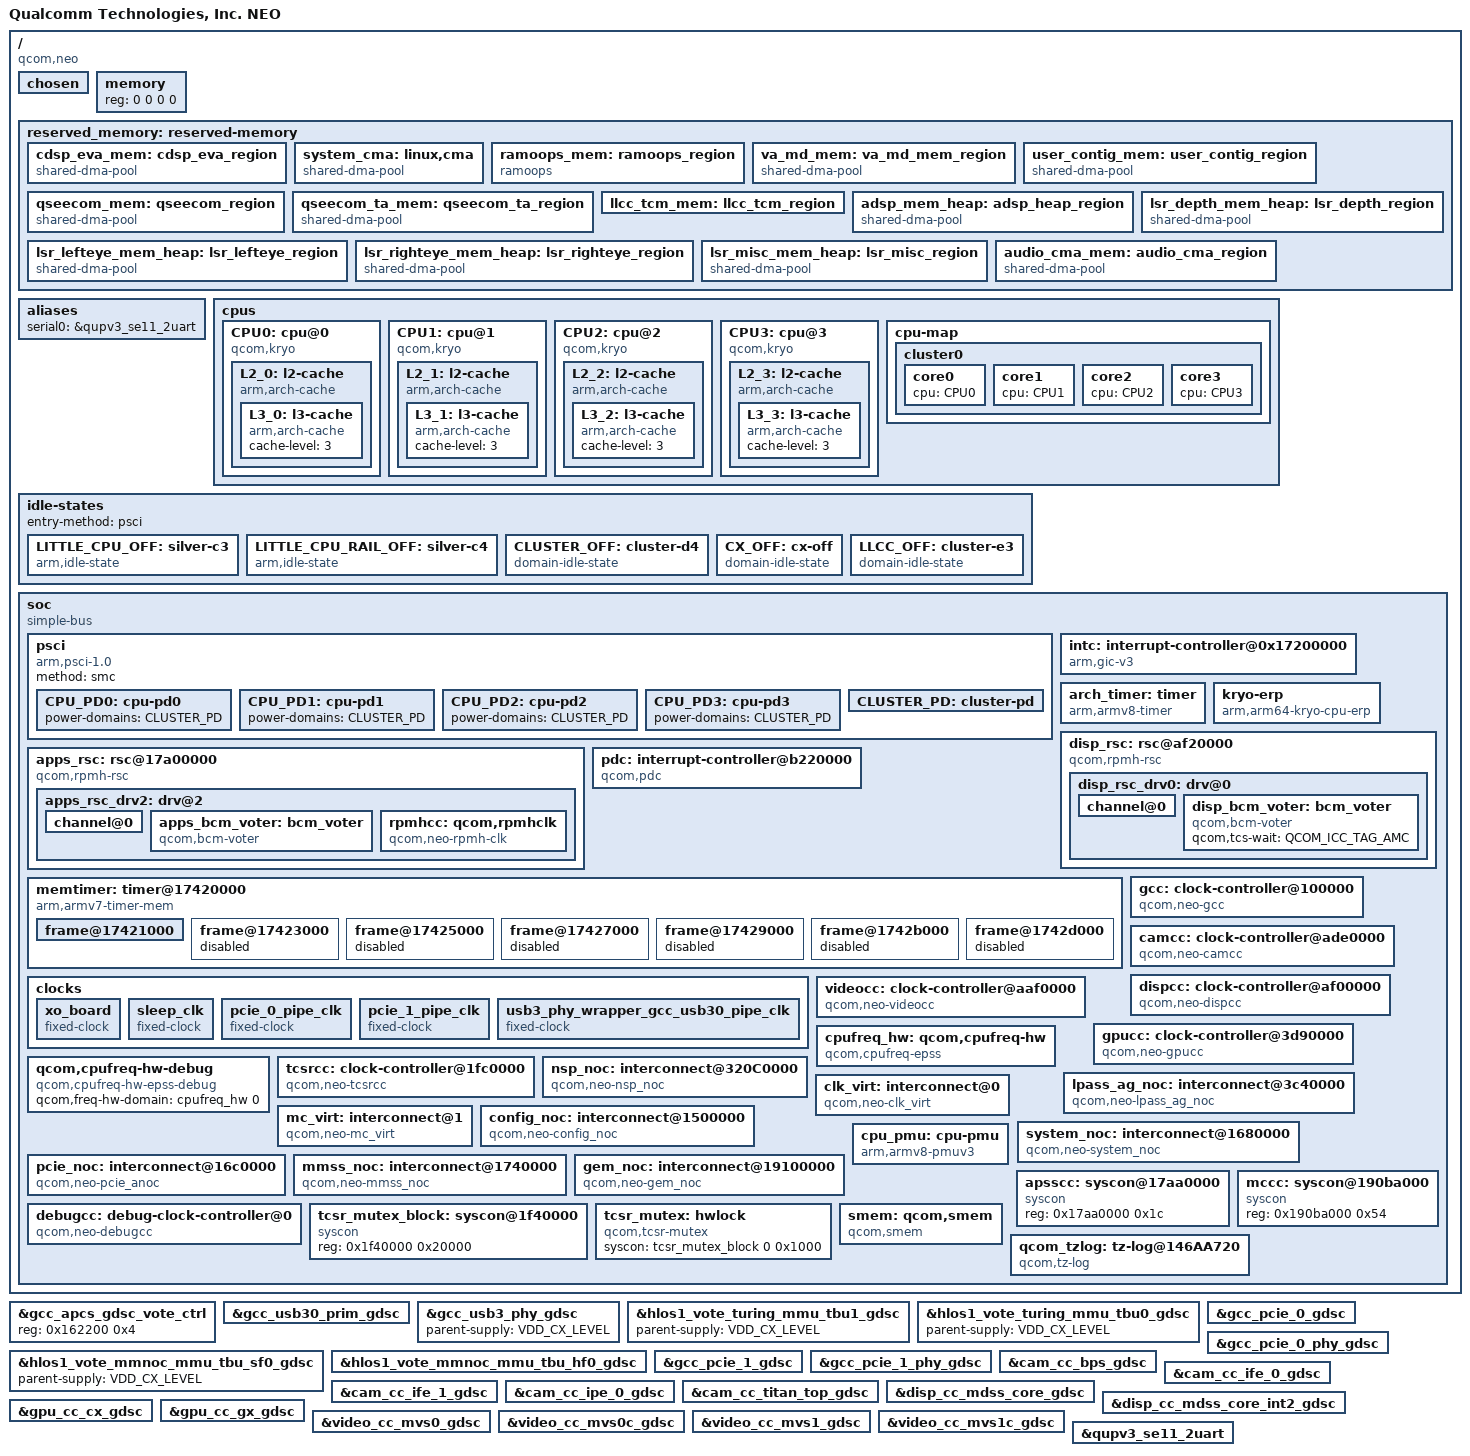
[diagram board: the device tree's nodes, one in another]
#include <dt-bindings/interrupt-controller/arm-gic.h>
#include <dt-bindings/clock/qcom,rpmh.h>
#include <dt-bindings/clock/qcom,gcc-neo.h>
#include <dt-bindings/clock/qcom,gpucc-neo.h>
#include <dt-bindings/clock/qcom,camcc-neo.h>
#include <dt-bindings/clock/qcom,dispcc-neo.h>
#include <dt-bindings/clock/qcom,tcsrcc-neo.h>
#include <dt-bindings/clock/qcom,videocc-neo.h>
#include <dt-bindings/interconnect/qcom,icc.h>
#include <dt-bindings/interconnect/qcom,neo.h>
#include <dt-bindings/soc/qcom,rpmh-rsc.h>

/ {
	model = "Qualcomm Technologies, Inc. NEO";
	compatible = "qcom,neo";
	qcom,msm-id = <525 0x10000>;
	interrupt-parent = <&intc>;

	#address-cells = <2>;
	#size-cells = <2>;

	chosen: chosen {
		bootargs = " rcupdate.rcu_expedited=1 rcu_nocbs=0-7 kpti=off log_buf_len=256K pcie_ports=compat console=ttyMSM0,115200,n8 loglevel=6 cpufreq.default_governor=performance swiotlb=noforce cgroup.memory=nokmem,nosocket allow_file_spec_access msm_rtb.filter=0x237 disable_dma32=on ftrace_dump_on_oops net.ifnames=0";
	};

	memory { device_type = "memory"; reg = <0 0 0 0>; };

	reserved_memory: reserved-memory { };

	aliases: aliases {
		serial0 = &qupv3_se11_2uart;
	};

	cpus {
		#address-cells = <2>;
		#size-cells = <0>;

		CPU0: cpu@0 {
			device_type = "cpu";
			compatible = "qcom,kryo";
			reg = <0x0 0x0>;
			enable-method = "psci";
			next-level-cache = <&L2_0>;
			cpu-idle-states = <&LITTLE_CPU_OFF &LITTLE_CPU_RAIL_OFF>;
			power-domains = <&CPU_PD0>;
			power-domain-names = "psci";
			capacity-dmips-mhz = <1024>;
			dynamic-power-coefficient = <100>;
			#cooling-cells = <2>;
			qcom,freq-domain = <&cpufreq_hw 0>;
			L2_0: l2-cache {
				compatible = "arm,arch-cache";
				cache-level = <2>;
				next-level-cache = <&L3_0>;

				L3_0: l3-cache {
					compatible = "arm,arch-cache";
					cache-level = <3>;
				};
			};
		};

		CPU1: cpu@1 {
			device_type = "cpu";
			compatible = "qcom,kryo";
			reg = <0x0 0x100>;
			enable-method = "psci";
			next-level-cache = <&L2_1>;
			cpu-idle-states = <&LITTLE_CPU_OFF &LITTLE_CPU_RAIL_OFF>;
			power-domains = <&CPU_PD1>;
			power-domain-names = "psci";
			capacity-dmips-mhz = <1024>;
			dynamic-power-coefficient = <100>;
			#cooling-cells = <2>;
			qcom,freq-domain = <&cpufreq_hw 0>;
			L2_1: l2-cache {
				compatible = "arm,arch-cache";
				cache-level = <2>;
				next-level-cache = <&L3_1>;

				L3_1: l3-cache {
					compatible = "arm,arch-cache";
					cache-level = <3>;
				};
			};
		};

		CPU2: cpu@2 {
			device_type = "cpu";
			compatible = "qcom,kryo";
			reg = <0x0 0x200>;
			enable-method = "psci";
			next-level-cache = <&L2_2>;
			cpu-idle-states = <&LITTLE_CPU_OFF &LITTLE_CPU_RAIL_OFF>;
			power-domains = <&CPU_PD2>;
			power-domain-names = "psci";
			capacity-dmips-mhz = <1024>;
			dynamic-power-coefficient = <100>;
			#cooling-cells = <2>;
			qcom,freq-domain = <&cpufreq_hw 0>;
			L2_2: l2-cache {
				compatible = "arm,arch-cache";
				cache-level = <2>;
				next-level-cache = <&L3_2>;

				L3_2: l3-cache {
					compatible = "arm,arch-cache";
					cache-level = <3>;
				};
			};
		};

		CPU3: cpu@3 {
			device_type = "cpu";
			compatible = "qcom,kryo";
			reg = <0x0 0x300>;
			enable-method = "psci";
			next-level-cache = <&L2_3>;
			cpu-idle-states = <&LITTLE_CPU_OFF &LITTLE_CPU_RAIL_OFF>;
			power-domains = <&CPU_PD3>;
			power-domain-names = "psci";
			capacity-dmips-mhz = <1024>;
			dynamic-power-coefficient = <100>;
			#cooling-cells = <2>;
			qcom,freq-domain = <&cpufreq_hw 0>;
			L2_3: l2-cache {
				compatible = "arm,arch-cache";
				cache-level = <2>;
				next-level-cache = <&L3_3>;

				L3_3: l3-cache {
					compatible = "arm,arch-cache";
					cache-level = <3>;
				};
			};
		};

		cpu-map {
			cluster0 {
				core0 {
					cpu = <&CPU0>;
				};

				core1 {
					cpu = <&CPU1>;
				};

				core2 {
					cpu = <&CPU2>;
				};

				core3 {
					cpu = <&CPU3>;
				};
			};
		};
	};

	idle-states {
		entry-method = "psci";

		LITTLE_CPU_OFF: silver-c3 {  /* C3 */
			compatible = "arm,idle-state";
			idle-state-name = "pc";
			entry-latency-us = <549>;
			exit-latency-us = <901>;
			min-residency-us = <1774>;
			arm,psci-suspend-param = <0x40000003>;
			local-timer-stop;
		};

		LITTLE_CPU_RAIL_OFF: silver-c4 {  /* C4 */
			compatible = "arm,idle-state";
			idle-state-name = "rail-pc";
			entry-latency-us = <702>;
			exit-latency-us = <915>;
			min-residency-us = <4001>;
			arm,psci-suspend-param = <0x40000004>;
			local-timer-stop;
		};

		CLUSTER_OFF: cluster-d4 { /* D4 */
			compatible = "domain-idle-state";
			idle-state-name = "l3-off";
			entry-latency-us = <2752>;
			exit-latency-us = <3048>;
			min-residency-us = <6118>;
			arm,psci-suspend-param = <0x41000044>;
		};

		CX_OFF: cx-off { /* Cx Off */
			compatible = "domain-idle-state";
			idle-state-name = "cx-off";
			entry-latency-us = <3263>;
			exit-latency-us = <4562>;
			min-residency-us = <8467>;
			arm,psci-suspend-param = <0x41002344>;
		};

		LLCC_OFF: cluster-e3 { /* E3 */
			compatible = "domain-idle-state";
			idle-state-name = "llcc-off";
			entry-latency-us = <3638>;
			exit-latency-us = <6562>;
			min-residency-us = <9826>;
			arm,psci-suspend-param = <0x4100C344>;
		};
	};

	soc: soc { };

};

#include "neo-reserved-memory.dtsi"

&reserved_memory {
	#address-cells = <2>;
	#size-cells = <2>;
	ranges;

	cdsp_eva_mem: cdsp_eva_region {
			compatible = "shared-dma-pool";
			alloc-ranges = <0x0 0x00000000 0x0 0xffffffff>;
			reusable;
			alignment = <0x0 0x400000>;
			size = <0x0 0x400000>;
	};

	/* global autoconfigured region for contiguous allocations */
	system_cma: linux,cma {
		compatible = "shared-dma-pool";
		alloc-ranges = <0x0 0x00000000 0x0 0xffffffff>;
		reusable;
		alignment = <0x0 0x400000>;
		size = <0x0 0x1000000>;
		linux,cma-default;
	};

	ramoops_mem: ramoops_region {
		compatible = "ramoops";
		alloc-ranges = <0x0 0x00000000 0xffffffff 0xffffffff>;
		size = <0x0 0x200000>;
		pmsg-size = <0x200000>;
		mem-type = <2>;
	};

	va_md_mem: va_md_mem_region {
		compatible = "shared-dma-pool";
		alloc-ranges = <0x0 0x00000000 0x0 0xffffffff>;
		reusable;
		size = <0 0x1000000>;
	};

	user_contig_mem: user_contig_region {
		compatible = "shared-dma-pool";
		alloc-ranges = <0x0 0x00000000 0x0 0xffffffff>;
		reusable;
		alignment = <0x0 0x400000>;
		size = <0x0 0x400000>;
	};

	qseecom_mem: qseecom_region {
		compatible = "shared-dma-pool";
		alloc-ranges = <0x0 0x00000000 0x0 0xffffffff>;
		reusable;
		alignment = <0x0 0x400000>;
		size = <0x0 0x400000>;
	};

	qseecom_ta_mem: qseecom_ta_region {
		compatible = "shared-dma-pool";
		alloc-ranges = <0x0 0x00000000 0x0 0xffffffff>;
		reusable;
		alignment = <0x0 0x400000>;
		size = <0x0 0x400000>;
	};

	llcc_tcm_mem: llcc_tcm_region {
		no-map;
		reg = <0x0 0x15800000 0x0 0x800000>;
	};

	adsp_mem_heap: adsp_heap_region {
		compatible = "shared-dma-pool";
		alloc-ranges = <0x0 0x00000000 0x0 0xffffffff>;
		reusable;
		alignment = <0x0 0x400000>;
		size = <0x0 0x800000>;
	};

	lsr_lefteye_mem_heap: lsr_lefteye_region {
		compatible = "shared-dma-pool";
		alloc-ranges = <0x0 0x00000000 0x0 0xffffffff>;
		no-map;
		alignment = <0x0 0x400000>;
		size = <0x0 0x1000000>;
	};

	lsr_righteye_mem_heap: lsr_righteye_region {
		compatible = "shared-dma-pool";
		alloc-ranges = <0x0 0x00000000 0x0 0xffffffff>;
		no-map;
		alignment = <0x0 0x400000>;
		size = <0x0 0x1000000>;
	};

	lsr_depth_mem_heap: lsr_depth_region {
		compatible = "shared-dma-pool";
		alloc-ranges = <0x0 0x00000000 0x0 0xffffffff>;
		no-map;
		alignment = <0x0 0x400000>;
		size = <0x0 0x100000>;
	};

	lsr_misc_mem_heap: lsr_misc_region {
		compatible = "shared-dma-pool";
		alloc-ranges = <0x0 0x00000000 0x0 0xffffffff>;
		no-map;
		alignment = <0x0 0x400000>;
		size = <0x0 0x2800000>;
	};

	audio_cma_mem: audio_cma_region {
		compatible = "shared-dma-pool";
		alloc-ranges = <0x0 0x00000000 0x0 0xffffffff>;
		reusable;
		alignment = <0x0 0x400000>;
		size = <0x0 0x1000000>;
	};
};

&soc {
	#address-cells = <1>;
	#size-cells = <1>;
	ranges = <0 0 0 0xffffffff>;
	compatible = "simple-bus";

	psci {
		compatible = "arm,psci-1.0";
		method = "smc";

		CPU_PD0: cpu-pd0 {
			#power-domain-cells = <0>;
			power-domains = <&CLUSTER_PD>;
		};

		CPU_PD1: cpu-pd1 {
			#power-domain-cells = <0>;
			power-domains = <&CLUSTER_PD>;
		};

		CPU_PD2: cpu-pd2 {
			#power-domain-cells = <0>;
			power-domains = <&CLUSTER_PD>;
		};

		CPU_PD3: cpu-pd3 {
			#power-domain-cells = <0>;
			power-domains = <&CLUSTER_PD>;
		};

		CLUSTER_PD: cluster-pd {
			#power-domain-cells = <0>;
			domain-idle-states = <&CLUSTER_OFF &CX_OFF &LLCC_OFF>;
		};
	};

	intc: interrupt-controller@0x17200000 {
		compatible = "arm,gic-v3";
		#interrupt-cells = <3>;
		interrupt-controller;
		#redistributor-regions = <1>;
		redistributor-stride = <0x0 0x20000>;
		reg = <0x17200000 0x10000>,     /* GICD */
		      <0x17260000 0x100000>;    /* GICR * 8 */
		interrupts = <GIC_PPI 9 IRQ_TYPE_LEVEL_LOW>;
	};

	arch_timer: timer {
		compatible = "arm,armv8-timer";
		interrupts = <GIC_PPI 13 (GIC_CPU_MASK_SIMPLE(8) | IRQ_TYPE_LEVEL_LOW)>,
			     <GIC_PPI 14 (GIC_CPU_MASK_SIMPLE(8) | IRQ_TYPE_LEVEL_LOW)>,
			     <GIC_PPI 11 (GIC_CPU_MASK_SIMPLE(8) | IRQ_TYPE_LEVEL_LOW)>,
			     <GIC_PPI 12 (GIC_CPU_MASK_SIMPLE(8) | IRQ_TYPE_LEVEL_LOW)>;
		clock-frequency = <19200000>;
	};

	kryo-erp {
		compatible = "arm,arm64-kryo-cpu-erp";
		interrupts = <GIC_PPI 0 IRQ_TYPE_LEVEL_HIGH>,
			     <GIC_SPI 35 IRQ_TYPE_LEVEL_HIGH>;
		interrupt-names = "l1-l2-faultirq","l3-scu-faultirq";
	};

	apps_rsc: rsc@17a00000 {
		label = "apps_rsc";
		compatible = "qcom,rpmh-rsc";
		reg = <0x17a00000 0x10000>,
		      <0x17a10000 0x10000>,
		      <0x17a20000 0x10000>;
		reg-names = "drv-0", "drv-1", "drv-2";
		qcom,drv-count = <3>;
		interrupts = <GIC_SPI 3 IRQ_TYPE_LEVEL_HIGH>,
			     <GIC_SPI 4 IRQ_TYPE_LEVEL_HIGH>,
			     <GIC_SPI 5 IRQ_TYPE_LEVEL_HIGH>;
		power-domains = <&CLUSTER_PD>;

		apps_rsc_drv2: drv@2 {
			qcom,drv-id = <2>;
			qcom,tcs-offset = <0xd00>;
			channel@0 {
				qcom,tcs-config = <ACTIVE_TCS    3>,
						  <SLEEP_TCS     2>,
						  <WAKE_TCS      2>,
						  <FAST_PATH_TCS 1>,
						  <CONTROL_TCS   0>;
			};

			apps_bcm_voter: bcm_voter {
				compatible = "qcom,bcm-voter";
			};

			rpmhcc: qcom,rpmhclk {
				compatible = "qcom,neo-rpmh-clk";
				#clock-cells = <1>;
			};
		};
	};

	disp_rsc: rsc@af20000 {
		label = "disp_rsc";
		compatible = "qcom,rpmh-rsc";
		reg = <0xaf20000 0x10000>;
		reg-names = "drv-0";
		qcom,drv-count = <1>;
		interrupts = <GIC_SPI 129 IRQ_TYPE_LEVEL_HIGH>;

		disp_rsc_drv0: drv@0 {
			qcom,drv-id = <0>;
			qcom,tcs-offset = <0x1c00>;
			channel@0 {
				qcom,tcs-config = <ACTIVE_TCS    0>,
						  <SLEEP_TCS     1>,
						  <WAKE_TCS      1>,
						  <CONTROL_TCS   0>,
						  <FAST_PATH_TCS 0>;
			};

			disp_bcm_voter: bcm_voter {
				compatible = "qcom,bcm-voter";
				qcom,tcs-wait = <QCOM_ICC_TAG_AMC>;
			};
		};
	};

	pdc: interrupt-controller@b220000 {
		compatible = "qcom,pdc", "qcom,neo-pdc";
		reg = <0xb220000 0x30000>, <0x174000f0 0x64>;
		reg-names = "pdc-interrupt-base", "apss-shared-spi-cfg";
		qcom,pdc-ranges = <0 480 94>, <94 609 31>, <125 63 1>, <126 716 12>;
		#interrupt-cells = <2>;
		interrupt-parent = <&intc>;
		interrupt-controller;
	};

	memtimer: timer@17420000 {
		#address-cells = <1>;
		#size-cells = <1>;
		ranges;
		compatible = "arm,armv7-timer-mem";
		reg = <0x17420000 0x1000>;
		clock-frequency = <19200000>;

		frame@17421000 {
			frame-number = <0>;
			interrupts = <GIC_SPI 8 IRQ_TYPE_LEVEL_HIGH>,
				     <GIC_SPI 6 IRQ_TYPE_LEVEL_HIGH>;
			reg = <0x17421000 0x1000>,
			      <0x17422000 0x1000>;
		};

		frame@17423000 {
			frame-number = <1>;
			interrupts = <GIC_SPI 9 IRQ_TYPE_LEVEL_HIGH>;
			reg = <0x17423000 0x1000>;
			status = "disabled";
		};

		frame@17425000 {
			frame-number = <2>;
			interrupts = <GIC_SPI 10 IRQ_TYPE_LEVEL_HIGH>;
			reg = <0x17425000 0x1000>;
			status = "disabled";
		};

		frame@17427000 {
			frame-number = <3>;
			interrupts = <GIC_SPI 11 IRQ_TYPE_LEVEL_HIGH>;
			reg = <0x17427000 0x1000>;
			status = "disabled";
		};

		frame@17429000 {
			frame-number = <4>;
			interrupts = <GIC_SPI 12 IRQ_TYPE_LEVEL_HIGH>;
			reg = <0x17429000 0x1000>;
			status = "disabled";
		};

		frame@1742b000 {
			frame-number = <5>;
			interrupts = <GIC_SPI 13 IRQ_TYPE_LEVEL_HIGH>;
			reg = <0x1742b000 0x1000>;
			status = "disabled";
		};

		frame@1742d000 {
			frame-number = <6>;
			interrupts = <GIC_SPI 14 IRQ_TYPE_LEVEL_HIGH>;
			reg = <0x1742d000 0x1000>;
			status = "disabled";
		};
	};

	clocks {
		xo_board: xo_board {
			compatible = "fixed-clock";
			clock-frequency = <19200000>;
			clock-output-names = "xo_board";
			#clock-cells = <0>;
		};

		sleep_clk: sleep_clk {
			compatible = "fixed-clock";
			clock-frequency = <32000>;
			clock-output-names = "sleep_clk";
			#clock-cells = <0>;
		};

		pcie_0_pipe_clk: pcie_0_pipe_clk {
			compatible = "fixed-clock";
			clock-frequency = <1000>;
			clock-output-names = "pcie_0_pipe_clk";
			#clock-cells = <0>;
		};

		pcie_1_pipe_clk: pcie_1_pipe_clk {
			compatible = "fixed-clock";
			clock-frequency = <1000>;
			clock-output-names = "pcie_1_pipe_clk";
			#clock-cells = <0>;
		};

		usb3_phy_wrapper_gcc_usb30_pipe_clk: usb3_phy_wrapper_gcc_usb30_pipe_clk {
			compatible = "fixed-clock";
			clock-frequency = <1000>;
			clock-output-names = "usb3_phy_wrapper_gcc_usb30_pipe_clk";
			#clock-cells = <0>;
		};
	};

	gcc: clock-controller@100000 {
		compatible = "qcom,neo-gcc", "syscon";
		reg = <0x100000 0x1f4200>;
		reg-name = "cc_base";
		vdd_cx-supply = <&VDD_CX_LEVEL>;
		vdd_mxa-supply = <&VDD_MXA_LEVEL>;
		clocks = <&rpmhcc RPMH_CXO_CLK>, <&sleep_clk>,
			<&pcie_0_pipe_clk>, <&pcie_1_pipe_clk>,
			<&usb3_phy_wrapper_gcc_usb30_pipe_clk>;
		clock-names = "bi_tcxo", "sleep_clk",
			"pcie_0_pipe_clk", "pcie_1_pipe_clk",
			"usb3_phy_wrapper_gcc_usb30_pipe_clk";
		#clock-cells = <1>;
		#reset-cells = <1>;
	};

	camcc: clock-controller@ade0000 {
		compatible = "qcom,neo-camcc", "syscon";
		reg = <0xade0000 0x20000>;
		reg-name = "cc_base";
		vdd_mm-supply = <&VDD_MM_LEVEL>;
		vdd_mxa-supply = <&VDD_MXA_LEVEL>;
		vdd_mxc-supply = <&VDD_MXC_LEVEL>;
		clocks = <&rpmhcc RPMH_CXO_CLK>,
			<&sleep_clk>,
			<&gcc GCC_CAMERA_AHB_CLK>;
		clock-names = "bi_tcxo",
			"sleep_clk", "iface";
		#clock-cells = <1>;
		#reset-cells = <1>;
	};

	dispcc: clock-controller@af00000 {
		compatible = "qcom,neo-dispcc", "syscon";
		reg = <0xaf00000 0x20000>;
		reg-name = "cc_base";
		vdd_mm-supply = <&VDD_MM_LEVEL>;
		vdd_mxa-supply = <&VDD_MXA_LEVEL>;
		clocks = <&rpmhcc RPMH_CXO_CLK>,
			<&rpmhcc RPMH_CXO_CLK_A>,
			<&sleep_clk>,
			<&gcc GCC_DISP_AHB_CLK>;
		clock-names = "bi_tcxo", "bi_tcxo_ao", "sleep_clk", "iface";
		#clock-cells = <1>;
		#reset-cells = <1>;
	};

	videocc: clock-controller@aaf0000 {
		compatible = "qcom,neo-videocc", "syscon";
		reg = <0xaaf0000 0x10000>;
		reg-name = "cc_base";
		vdd_mm-supply = <&VDD_MM_LEVEL>;
		vdd_mxc-supply = <&VDD_MXC_LEVEL>;
		clocks = <&rpmhcc RPMH_CXO_CLK>,
			<&sleep_clk>,
			<&gcc GCC_VIDEO_AHB_CLK>;
		clock-names = "bi_tcxo", "sleep_clk",
			"iface";
		#clock-cells = <1>;
		#reset-cells = <1>;
	};

	gpucc: clock-controller@3d90000 {
		compatible = "qcom,neo-gpucc", "syscon";
		reg = <0x3d90000 0xa000>;
		reg-name = "cc_base";
		vdd_cx-supply = <&VDD_CX_LEVEL>;
		vdd_mxa-supply = <&VDD_MXA_LEVEL>;
		clocks = <&rpmhcc RPMH_CXO_CLK>,
			<&gcc GCC_GPU_GPLL0_CLK_SRC>,
			<&gcc GCC_GPU_GPLL0_DIV_CLK_SRC>;
		clock-names = "bi_tcxo",
			"gpll0_out_main",
			"gpll0_out_main_div";
		#clock-cells = <1>;
		#reset-cells = <1>;
	};

	cpufreq_hw: qcom,cpufreq-hw {
		compatible = "qcom,cpufreq-epss";
		reg = <0x17d91000 0x1000>;
		reg-names = "freq-domain0";
		clocks = <&rpmhcc RPMH_CXO_CLK>, <&gcc GCC_GPLL0>;
		clock-names = "xo", "alternate";
		interrupts = <GIC_SPI 30 IRQ_TYPE_LEVEL_HIGH>;
		interrupt-names = "dcvsh0_int";
		#freq-domain-cells = <1>;
	};

	qcom,cpufreq-hw-debug {
		compatible = "qcom,cpufreq-hw-epss-debug";
		qcom,freq-hw-domain = <&cpufreq_hw 0>;
	};

	tcsrcc: clock-controller@1fc0000 {
		compatible = "qcom,neo-tcsrcc", "syscon";
		reg = <0x1fc0000 0x30000>;
		reg-name = "cc_base";
		#clock-cells = <1>;
		#reset-cells = <1>;
	};

	nsp_noc: interconnect@320C0000 {
		reg = <0x320C0000 0x10>;
		compatible = "qcom,neo-nsp_noc";
		qcom,bcm-voter-names = "hlos";
		qcom,bcm-voters = <&apps_bcm_voter>;
		#interconnect-cells = <1>;
	};

	lpass_ag_noc: interconnect@3c40000 {
		reg = <0x3c40000 0x10>;
		compatible = "qcom,neo-lpass_ag_noc";
		qcom,bcm-voter-names = "hlos";
		qcom,bcm-voters = <&apps_bcm_voter>;
		#interconnect-cells = <1>;
	};

	clk_virt: interconnect@0 {
		compatible = "qcom,neo-clk_virt";
		qcom,bcm-voter-names = "hlos";
		qcom,bcm-voters = <&apps_bcm_voter>;
		#interconnect-cells = <1>;
	};

	mc_virt: interconnect@1 {
		compatible = "qcom,neo-mc_virt";
		qcom,bcm-voter-names = "hlos", "disp";
		qcom,bcm-voters = <&apps_bcm_voter>, <&disp_bcm_voter>;
		#interconnect-cells = <1>;
	};

	config_noc: interconnect@1500000 {
		reg = <0x1500000 0x10>;
		compatible = "qcom,neo-config_noc";
		qcom,bcm-voter-names = "hlos";
		qcom,bcm-voters = <&apps_bcm_voter>;
		#interconnect-cells = <1>;
	};

	system_noc: interconnect@1680000 {
		reg = <0x1680000 0x29080>;
		compatible = "qcom,neo-system_noc";
		qcom,bcm-voter-names = "hlos";
		qcom,bcm-voters = <&apps_bcm_voter>;
		#interconnect-cells = <1>;
		clocks = <&gcc GCC_AGGRE_USB3_PRIM_AXI_CLK>;
	};

	pcie_noc: interconnect@16c0000 {
		reg = <0x16c0000 0xA080>;
		compatible = "qcom,neo-pcie_anoc";
		qcom,bcm-voter-names = "hlos";
		qcom,bcm-voters = <&apps_bcm_voter>;
		#interconnect-cells = <1>;
		clocks =  <&gcc GCC_AGGRE_NOC_PCIE_1_AXI_CLK>,
			<&gcc GCC_CFG_NOC_PCIE_ANOC_AHB_CLK>;
	};

	mmss_noc: interconnect@1740000 {
		reg = <0x1740000 0x1F100>;
		compatible = "qcom,neo-mmss_noc";
		qcom,bcm-voter-names = "hlos", "disp";
		qcom,bcm-voters = <&apps_bcm_voter>, <&disp_bcm_voter>;
		#interconnect-cells = <1>;
	};

	gem_noc: interconnect@19100000 {
		reg = <0x19100000 0xA2080>;
		compatible = "qcom,neo-gem_noc";
		qcom,bcm-voter-names = "hlos", "disp";
		qcom,bcm-voters = <&apps_bcm_voter>, <&disp_bcm_voter>;
		#interconnect-cells = <1>;
	};

	cpu_pmu: cpu-pmu {
		compatible = "arm,armv8-pmuv3";
		qcom,irq-is-percpu;
		interrupts = <GIC_PPI 7 IRQ_TYPE_LEVEL_LOW>;
	};

	apsscc: syscon@17aa0000 {
		compatible = "syscon";
		reg = <0x17aa0000 0x1c>;
	};

	mccc: syscon@190ba000 {
		compatible = "syscon";
		reg = <0x190ba000 0x54>;
	};

	debugcc: debug-clock-controller@0 {
		compatible = "qcom,neo-debugcc";
		qcom,gcc = <&gcc>;
		qcom,videocc = <&videocc>;
		qcom,camcc = <&camcc>;
		qcom,gpucc = <&gpucc>;
		qcom,dispcc = <&dispcc>;
		qcom,apsscc = <&apsscc>;
		qcom,mccc = <&mccc>;
		clock-names = "xo_clk_src",
				"gcc",
				"videocc",
				"dispcc",
				"camcc",
				"gpucc";
		clocks = <&rpmhcc RPMH_CXO_CLK>,
			<&gcc 0>,
			<&videocc 0>,
			<&dispcc 0>,
			<&camcc 0>,
			<&gpucc 0>;
		#clock-cells = <1>;
	};

	tcsr_mutex_block: syscon@1f40000 {
		compatible = "syscon";
		reg = <0x1f40000 0x20000>;
	};

	tcsr_mutex: hwlock {
		compatible = "qcom,tcsr-mutex";
		syscon = <&tcsr_mutex_block 0 0x1000>;
		#hwlock-cells = <1>;
	};

	smem: qcom,smem {
		compatible = "qcom,smem";
		memory-region = <&smem_mem>;
		hwlocks = <&tcsr_mutex 3>;
	};

	qcom_tzlog: tz-log@146AA720 {
		compatible = "qcom,tz-log";
		reg = <0x146AA720 0x3000>;
		qcom,hyplog-enabled;
		hyplog-address-offset = <0x410>;
		hyplog-size-offset = <0x414>;
		tmecrashdump-address-offset = <0x808a0000>;
	};

};

#include "neo-dma-heaps.dtsi"
#include "neo-pinctrl.dtsi"
#include "anorak-gdsc.dtsi"
#include "neo-qupv3.dtsi"

&gcc_apcs_gdsc_vote_ctrl {
	reg = <0x162200 0x4>;
};

&gcc_usb30_prim_gdsc {
	parent-supply = <&VDD_CX_LEVEL>;
	qcom,support-hw-trigger;
	status = "ok";
};

&gcc_usb3_phy_gdsc {
	parent-supply = <&VDD_CX_LEVEL>;
	status = "ok";
};

&hlos1_vote_turing_mmu_tbu1_gdsc {
	parent-supply = <&VDD_CX_LEVEL>;
	status = "ok";
};

&hlos1_vote_turing_mmu_tbu0_gdsc {
	parent-supply = <&VDD_CX_LEVEL>;
	status = "ok";
};

&hlos1_vote_mmnoc_mmu_tbu_sf0_gdsc {
	parent-supply = <&VDD_CX_LEVEL>;
	status = "ok";
};

&hlos1_vote_mmnoc_mmu_tbu_hf0_gdsc {
	parent-supply = <&VDD_CX_LEVEL>;
	reg = <0x18d204 0x4>;
	status = "ok";
};

&gcc_pcie_0_gdsc {
	parent-supply = <&VDD_CX_LEVEL>;
	status = "ok";
	/delete-property/ qcom,support-hw-trigger;
	qcom,collapse-vote = <&gcc_apcs_gdsc_vote_ctrl &gcc_apcs_gdsc_sleep_ctrl 0>;
};

&gcc_pcie_0_phy_gdsc {
	parent-supply = <&VDD_MXA_LEVEL>;
	status = "ok";
	qcom,collapse-vote = <&gcc_apcs_gdsc_vote_ctrl &gcc_apcs_gdsc_sleep_ctrl 3>;
};

&gcc_pcie_1_gdsc {
	parent-supply = <&VDD_CX_LEVEL>;
	status = "ok";
	qcom,collapse-vote = <&gcc_apcs_gdsc_vote_ctrl &gcc_apcs_gdsc_sleep_ctrl 1>;
};

&gcc_pcie_1_phy_gdsc {
	parent-supply = <&VDD_MXA_LEVEL>;
	status = "ok";
	qcom,collapse-vote = <&gcc_apcs_gdsc_vote_ctrl &gcc_apcs_gdsc_sleep_ctrl 4>;
};

&cam_cc_bps_gdsc {
	clocks = <&gcc GCC_CAMERA_AHB_CLK>;
	clock-names = "ahb_clk";
	parent-supply = <&VDD_MM_MXC_VOTER_LEVEL>;
	reg = <0xadf0004 0x4>;
	status = "ok";
};

&cam_cc_ife_0_gdsc {
	clocks = <&gcc GCC_CAMERA_AHB_CLK>;
	clock-names = "ahb_clk";
	parent-supply = <&VDD_MM_MXC_VOTER_LEVEL>;
	reg = <0xadf1004 0x4>;
	status = "ok";
};

&cam_cc_ife_1_gdsc {
	clocks = <&gcc GCC_CAMERA_AHB_CLK>;
	clock-names = "ahb_clk";
	parent-supply = <&VDD_MM_MXC_VOTER_LEVEL>;
	reg = <0xadf2004 0x4>;
	status = "ok";
};

&cam_cc_ipe_0_gdsc {
	clocks = <&gcc GCC_CAMERA_AHB_CLK>;
	clock-names = "ahb_clk";
	parent-supply = <&VDD_MM_MXC_VOTER_LEVEL>;
	reg = <0xadf03b8 0x4>;
	status = "ok";
};

&cam_cc_titan_top_gdsc {
	clocks = <&gcc GCC_CAMERA_AHB_CLK>;
	clock-names = "ahb_clk";
	parent-supply = <&VDD_MM_MXC_VOTER_LEVEL>;
	reg = <0xadf4000 0x4>;
	status = "ok";
};

&disp_cc_mdss_core_gdsc {
	clocks = <&gcc GCC_DISP_AHB_CLK>;
	clock-names = "ahb_clk";
	parent-supply = <&VDD_MM_LEVEL>;
	status = "ok";
};

&disp_cc_mdss_core_int2_gdsc {
	clocks = <&gcc GCC_DISP_AHB_CLK>;
	clock-names = "ahb_clk";
	parent-supply = <&VDD_MM_LEVEL>;
	status = "ok";
};

&gpu_cc_cx_gdsc {
	clocks = <&gcc GCC_GPU_CFG_AHB_CLK>;
	clock-names = "ahb_clk";
	parent-supply = <&VDD_CX_LEVEL>;
	status = "ok";
};

&gpu_cc_gx_gdsc {
	clocks = <&gcc GCC_GPU_CFG_AHB_CLK>;
	clocks-names = "ahb_clk";
	parent-supply = <&VDD_GFX_MXC_VOTER_LEVEL>;
	status = "ok";
};

&video_cc_mvs0_gdsc {
	clocks = <&gcc GCC_VIDEO_AHB_CLK>;
	clock-names = "ahb_clk";
	parent-supply = <&VDD_MM_MXC_VOTER_LEVEL>;
	reg = <0xaaf80a4 0x4>;
	status = "ok";
};

&video_cc_mvs0c_gdsc {
	clocks = <&gcc GCC_VIDEO_AHB_CLK>;
	clock-names = "ahb_clk";
	parent-supply = <&VDD_MM_MXC_VOTER_LEVEL>;
	reg = <0xaaf804c 0x4>;
	status = "ok";
};

&video_cc_mvs1_gdsc {
	clocks = <&gcc GCC_VIDEO_AHB_CLK>;
	clock-names = "ahb_clk";
	parent-supply = <&VDD_MM_MXC_VOTER_LEVEL>;
	reg = <0xaaf80cc 0x4>;
	status = "ok";
};

&video_cc_mvs1c_gdsc {
	clocks = <&gcc GCC_VIDEO_AHB_CLK>;
	clock-names = "ahb_clk";
	parent-supply = <&VDD_MM_MXC_VOTER_LEVEL>;
	reg = <0xaaf8078 0x4>;
	status = "ok";

};

&qupv3_se11_2uart {
	status = "ok";
};

#include "neo-regulators.dtsi"
#include "msm-arm-smmu-neo.dtsi"
